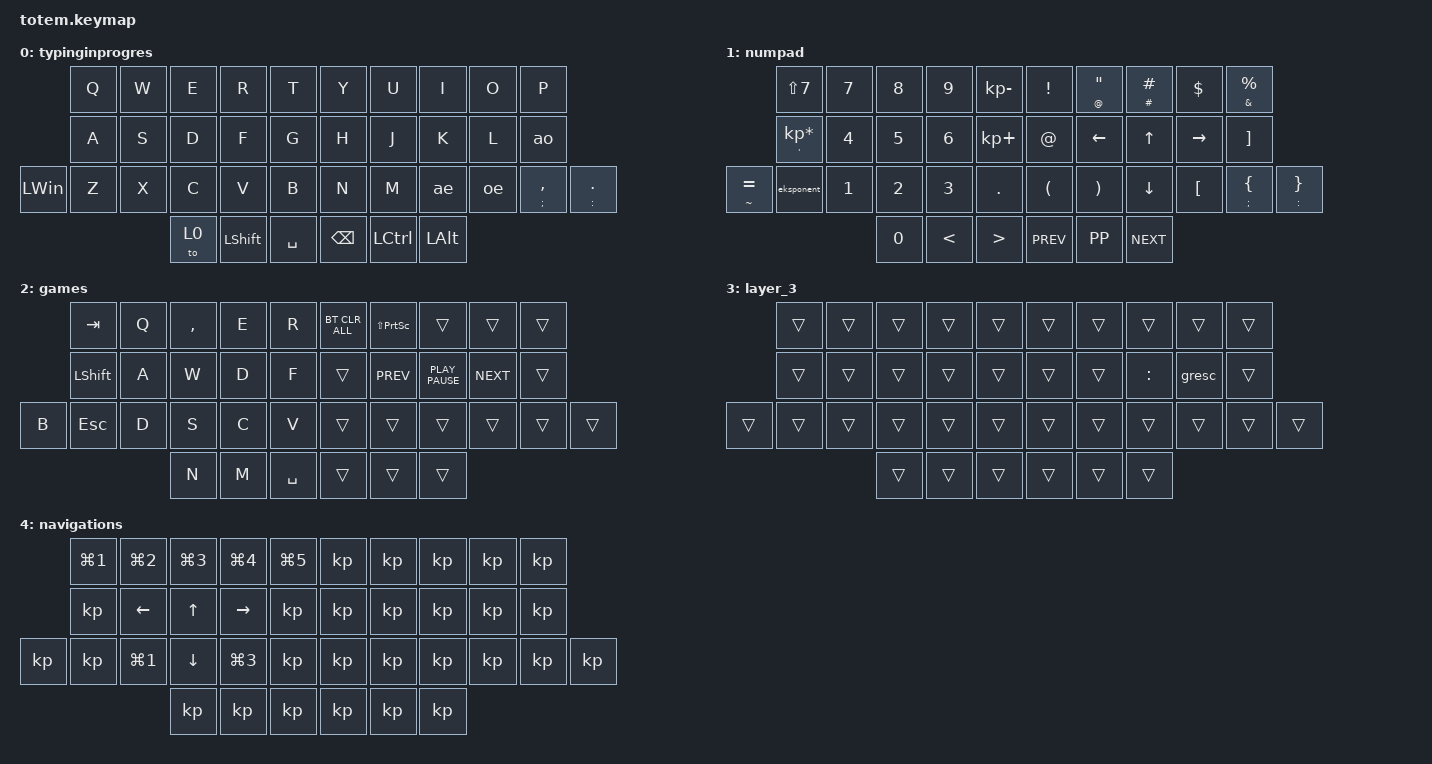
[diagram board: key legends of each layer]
//
//                                                        ▀▀▀▀▀     ▀▀▀▀▀          ▀▀█▀▀
//                                                        ▄▀▀▀▄  ▄  ▄▀▀▀▄  ▄  ▄▀▀▀▄  █  ▄▀▀▀▄
//                                                        █   █  █  █   █  █  █   █  █  █   █
//                                                         ▀▀▀   █   ▀▀▀   █   ▀▀▀   ▀   ▀▀▀
//                                                               █      ▄▄▄█▄▄▄    █   █  
//                                                               ▀      █  █  █     █▄█
//                                                             ▀▀▀▀▀    █  █  █      ▀
//                                                                      ▀  ▀  ▀
//
// ▄▄▄▄▄▄▄▄▄▄▄▄▄▄▄▄▄▄▄▄▄▄▄▄▄▄▄▄▄▄▄▄▄▄▄▄▄▄▄▄▄▄▄▄▄▄▄▄▄▄▄▄▄▄▄▄▄▄▄▄▄▄▄▄▄▄▄▄▄▄▄▄▄▄▄▄▄▄▄▄▄▄▄▄▄▄▄▄▄▄▄▄▄▄▄▄▄▄▄▄▄▄▄▄▄▄▄▄▄▄▄▄▄▄▄▄▄▄▄▄▄▄▄▄▄▄▄▄▄▄▄▄▄▄▄▄▄▄▄▄▄▄▄▄▄▄▄▄▄

#include <behaviors.dtsi>
#include <dt-bindings/zmk/bt.h>
#include <dt-bindings/zmk/keys.h>

#define BASE 0
#define NAV  1
#define SYM  2
#define ADJ  3
#define TVP1 4
#define TVP2 5

&mt {
    quick-tap-ms = <100>;
    global-quick-tap;
    flavor = "tap-preferred";
    tapping-term-ms = <170>;
};

/ {
    combos {
        compatible = "zmk,combos";

        enter {
            bindings = <&kp ENTER>;
            key-positions = <16 17 18>;
        };

        numpad {
            bindings = <&tog 1>;
            key-positions = <27 28 29>;
        };

        gamlayer {
            bindings = <&tog 2>;
            key-positions = <35 36 37>;
        };

        escape {
            bindings = <&kp ESCAPE>;
            key-positions = <1 0>;
        };

        sdfsd {
            bindings = <&tog 3>;
            key-positions = <12 17>;
        };
    };

    macros {
        gif: gif {
            label = "giphy";
            compatible = "zmk,behavior-macro";
            #binding-cells = <0>;
            bindings =
                <&macro_press>,
                <&kp LSHFT>,
                <&macro_tap>,
                <&kp N2>,
                <&macro_release>,
                <&kp LSHFT>,
                <&macro_tap>,
                <&kp G &kp I &kp F>;
        };

        ae: nords {
            compatible = "zmk,behavior-macro";
            #binding-cells = <0>;
            bindings = <&macro_tap>, <&kp LC(LS(U)) &kp E &kp N6 &kp SPACE>;

            label = "NORDS";
        };

        oe: oe {
            compatible = "zmk,behavior-macro";
            #binding-cells = <0>;
            bindings = <&macro_tap>, <&kp LC(LS(U)) &kp LS(F) &kp N8 &kp SPACE>;

            label = "OE";
        };

        ao: ao {
            compatible = "zmk,behavior-macro";
            #binding-cells = <0>;
            bindings = <&macro_tap>, <&kp LC(LS(U)) &kp LS(E) &kp N5 &kp SPACE>;

            label = "AO";
        };

        eksponent: eksponent {
            compatible = "zmk,behavior-macro";
            #binding-cells = <0>;
            bindings = <&macro_tap>, <&kp CARET>;

            label = "EKSPONENT";
        };
    };

    keymap {
        compatible = "zmk,keymap";

        // ▄▄▄▄▄▄▄▄▄▄▄▄▄▄▄▄▄▄▄▄▄▄▄▄▄▄▄▄▄▄▄▄▄▄▄▄▄▄▄▄▄▄▄▄▄▄▄▄▄▄▄▄▄▄▄▄▄▄▄▄▄▄▄▄▄▄▄▄▄▄▄▄▄▄▄▄▄▄▄▄▄▄▄▄▄▄▄▄▄▄▄▄▄▄▄▄▄▄▄▄▄▄▄▄▄▄▄▄▄▄▄▄▄▄▄▄▄▄▄▄▄▄▄▄▄▄▄▄▄▄▄▄▄▄▄▄▄▄▄▄▄▄▄▄▄▄▄▄▄
        // ▄▄▄▄▄▄▄▄▄▄▄▄▄▄▄▄▄▄▄▄▄▄▄▄▄▄▄▄▄▄▄▄▄▄▄▄▄▄▄▄▄▄▄▄▄▄▄▄▄▄▄▄▄▄▄▄▄▄▄▄▄▄▄▄▄▄▄▄▄▄▄▄▄▄▄▄▄▄▄▄▄▄▄▄▄▄▄▄▄▄▄▄▄▄▄▄▄▄▄▄▄▄▄▄▄▄▄▄▄▄▄▄▄▄▄▄▄▄▄▄▄▄▄▄▄▄▄▄▄▄▄▄▄▄▄▄▄▄▄▄▄▄▄▄▄▄▄▄▄
        // ▄▄▄▄▄▄▄▄▄▄▄▄▄▄▄▄▄▄▄▄▄▄▄▄▄▄▄▄▄▄▄▄▄▄▄▄▄▄▄▄▄▄▄▄▄▄▄▄▄▄▄▄▄▄▄▄▄▄▄▄▄▄▄▄▄▄▄▄▄▄▄▄▄▄▄▄▄▄▄▄▄▄▄▄▄▄▄▄▄▄▄▄▄▄▄▄▄▄▄▄▄▄▄▄▄▄▄▄▄▄▄▄▄▄▄▄▄▄▄▄▄▄▄▄▄▄▄▄▄▄▄▄▄▄▄▄▄▄▄▄▄▄▄▄▄▄▄▄▄
        // ▄▄▄▄▄▄▄▄▄▄▄▄▄▄▄▄▄▄▄▄▄▄▄▄▄▄▄▄▄▄▄▄▄▄▄▄▄▄▄▄▄▄▄▄▄▄▄▄▄▄▄▄▄▄▄▄▄▄▄▄▄▄▄▄▄▄▄▄▄▄▄▄▄▄▄▄▄▄▄▄▄▄▄▄▄▄▄▄▄▄▄▄▄▄▄▄▄▄▄▄▄▄▄▄▄▄▄▄▄▄▄▄▄▄▄▄▄▄▄▄▄▄▄▄▄▄▄▄▄▄▄▄▄▄▄▄▄▄▄▄▄▄▄▄▄▄▄▄▄
        // ▄▄▄▄▄▄▄▄▄▄▄▄▄▄▄▄▄▄▄▄▄▄▄▄▄▄▄▄▄▄▄▄▄▄▄▄▄▄▄▄▄▄▄▄▄▄▄▄▄▄▄▄▄▄▄▄▄▄▄▄▄▄▄▄▄▄▄▄▄▄▄▄▄▄▄▄▄▄▄▄▄▄▄▄▄▄▄▄▄▄▄▄▄▄▄▄▄▄▄▄▄▄▄▄▄▄▄▄▄▄▄▄▄▄▄▄▄▄▄▄▄▄▄▄▄▄▄▄▄▄▄▄▄▄▄▄▄▄▄▄▄▄▄▄▄▄▄▄▄
        // ▄▄▄▄▄▄▄▄▄▄▄▄▄▄▄▄▄▄▄▄▄▄▄▄▄▄▄▄▄▄▄▄▄▄▄▄▄▄▄▄▄▄▄▄▄▄▄▄▄▄▄▄▄▄▄▄▄▄▄▄▄▄▄▄▄▄▄▄▄▄▄▄▄▄▄▄▄▄▄▄▄▄▄▄▄▄▄▄▄▄▄▄▄▄▄▄▄▄▄▄▄▄▄▄▄▄▄▄▄▄▄▄▄▄▄▄▄▄▄▄▄▄▄▄▄▄▄▄▄▄▄▄▄▄▄▄▄▄▄▄▄▄▄▄▄▄▄▄▄

        typinginprogres {
            bindings = <
              &kp Q  &kp W  &kp E  &kp R       &kp T        &kp Y          &kp U      &kp I         &kp O  &kp P
              &kp A  &kp S  &kp D  &kp F       &kp G        &kp H          &kp J      &kp K         &kp L  &ao
&kp LEFT_WIN  &kp Z  &kp X  &kp C  &kp V       &kp B        &kp N          &kp M      &ae           &oe    &mt SEMICOLON COMMA  &mt COLON DOT
                            &to 0  &kp LSHIFT  &kp SPACE    &kp BACKSPACE  &kp LCTRL  &kp LEFT_ALT
            >;
        };

        numpad {
            bindings = <
                 &kp LS(N7)                  &kp N7  &kp N8  &kp N9         &kp KP_MINUS        &kp EXCLAMATION       &mt AT DOUBLE_QUOTES   &mt POUND POUND  &kp DOLLAR        &mt AMPERSAND PERCENT
                 &mt APOSTROPHE KP_MULTIPLY  &kp N4  &kp N5  &kp N6         &kp KP_PLUS         &kp AT_SIGN           &kp LEFT               &kp UP           &kp RIGHT         &kp RIGHT_BRACKET
&mt TILDE EQUAL  &eksponent                  &kp N1  &kp N2  &kp N3         &kp DOT             &kp LEFT_PARENTHESIS  &kp RIGHT_PARENTHESIS  &kp DOWN         &kp LEFT_BRACKET  &mt SEMICOLON LEFT_BRACE  &mt COLON RIGHT_BRACE
                                                     &kp N0  &kp LESS_THAN  &kp GREATER_THAN    &kp K_PREV            &kp K_PP               &kp K_NEXT
            >;
        };

        games {
            bindings = <
       &kp TAB    &kp Q  &kp COMMA  &kp E  &kp R        &bt BT_CLR_ALL  &kp LS(PRINTSCREEN)  &trans            &trans      &trans
       &kp LSHFT  &kp A  &kp W      &kp D  &kp F        &trans          &kp K_PREV           &kp K_PLAY_PAUSE  &kp K_NEXT  &trans
&kp B  &kp ESC    &kp D  &kp S      &kp C  &kp V        &trans          &trans               &trans            &trans      &trans  &trans
                         &kp N      &kp M  &kp SPACE    &trans          &trans               &trans
            >;
        };

        layer_3 {
            bindings = <
        &trans  &trans  &trans  &trans  &trans    &trans  &trans  &trans     &trans  &trans
        &trans  &trans  &trans  &trans  &trans    &trans  &trans  &kp COLON  &gresc  &trans
&trans  &trans  &trans  &trans  &trans  &trans    &trans  &trans  &trans     &trans  &trans  &trans
                        &trans  &trans  &trans    &trans  &trans  &trans
            >;
        };

        navigations {
            bindings = <
     &kp LG(NUMBER_1)  &kp LG(NUMBER_2)  &kp LG(NUMBER_3)  &kp LG(NUMBER_4)  &kp LG(NUMBER_5)    &kp  &kp  &kp  &kp  &kp
     &kp               &kp LEFT_ARROW    &kp UP_ARROW      &kp RIGHT_ARROW   &kp                 &kp  &kp  &kp  &kp  &kp
&kp  &kp               &kp LG(NUMBER_1)  &kp DOWN_ARROW    &kp LG(NUMBER_3)  &kp                 &kp  &kp  &kp  &kp  &kp  &kp
                                         &kp               &kp               &kp                 &kp  &kp  &kp
            >;
        };
    };
};
